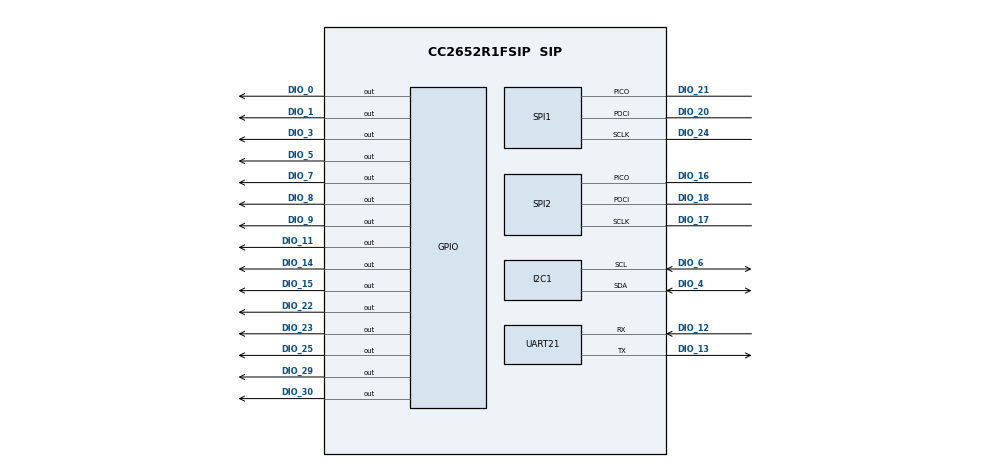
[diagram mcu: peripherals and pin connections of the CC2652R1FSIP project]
/**
 * @cliArgs --device "CC2652R1FSIP" --package "SIP" --part "Default" --rtos "tirtos7" --product "simplelink_cc13xx_cc26xx_sdk@7.41.00.17"
 * @versions {"tool":"1.18.1+3343"}
 */

/**
 * Import the modules used in this configuration.
 */
const ble            = scripting.addModule("/ti/ble5stack/ble");
const CCFG           = scripting.addModule("/ti/devices/CCFG");
const rfdesign       = scripting.addModule("/ti/devices/radioconfig/rfdesign");
const ADC            = scripting.addModule("/ti/drivers/ADC", {}, false);
const ADC1           = ADC.addInstance();
const AESCBC         = scripting.addModule("/ti/drivers/AESCBC", {}, false);
const AESCBC1        = AESCBC.addInstance();
const AESCCM         = scripting.addModule("/ti/drivers/AESCCM");
const AESCCM1        = AESCCM.addInstance();
const AESCTRDRBG     = scripting.addModule("/ti/drivers/AESCTRDRBG");
const AESCTRDRBG1    = AESCTRDRBG.addInstance();
const AESECB         = scripting.addModule("/ti/drivers/AESECB");
const AESECB1        = AESECB.addInstance();
const Board          = scripting.addModule("/ti/drivers/Board");
const ECDH           = scripting.addModule("/ti/drivers/ECDH");
const ECDH1          = ECDH.addInstance();
const GPIO           = scripting.addModule("/ti/drivers/GPIO");
const GPIO2          = GPIO.addInstance();
const GPIO3          = GPIO.addInstance();
const GPIO4          = GPIO.addInstance();
const GPIO5          = GPIO.addInstance();
const GPIO6          = GPIO.addInstance();
const GPIO7          = GPIO.addInstance();
const GPIO8          = GPIO.addInstance();
const GPIO9          = GPIO.addInstance();
const GPIO10         = GPIO.addInstance();
const GPIO11         = GPIO.addInstance();
const GPIO12         = GPIO.addInstance();
const GPIO13         = GPIO.addInstance();
const GPIO14         = GPIO.addInstance();
const GPIO15         = GPIO.addInstance();
const GPIO16         = GPIO.addInstance();
const I2C            = scripting.addModule("/ti/drivers/I2C", {}, false);
const I2C1           = I2C.addInstance();
const NVS            = scripting.addModule("/ti/drivers/NVS");
const NVS1           = NVS.addInstance();
const NVS2           = NVS.addInstance();
const Power          = scripting.addModule("/ti/drivers/Power");
const RF             = scripting.addModule("/ti/drivers/RF");
const SPI            = scripting.addModule("/ti/drivers/SPI", {}, false);
const SPI1           = SPI.addInstance();
const SPI2           = SPI.addInstance();
const TRNG           = scripting.addModule("/ti/drivers/TRNG");
const TRNG1          = TRNG.addInstance();
const TRNG2          = TRNG.addInstance();
const Timer          = scripting.addModule("/ti/drivers/Timer", {}, false);
const Timer1         = Timer.addInstance();
const UART2          = scripting.addModule("/ti/drivers/UART2", {}, false);
const UART21         = UART2.addInstance();
const Watchdog       = scripting.addModule("/ti/drivers/Watchdog", {}, false);
const Watchdog1      = Watchdog.addInstance();
const GPTimerCC26XX  = scripting.addModule("/ti/drivers/timer/GPTimerCC26XX", {}, false);
const GPTimerCC26XX2 = GPTimerCC26XX.addInstance();
const Settings       = scripting.addModule("/ti/posix/tirtos/Settings");
const BIOS           = scripting.addModule("/ti/sysbios/BIOS");
const GateMutexPri   = scripting.addModule("/ti/sysbios/gates/GateMutexPri");
const HeapCallback   = scripting.addModule("/ti/sysbios/heaps/HeapCallback");
const Event          = scripting.addModule("/ti/sysbios/knl/Event");
const Idle           = scripting.addModule("/ti/sysbios/knl/Idle", {}, false);
const Idle2          = Idle.addInstance();
const Mailbox        = scripting.addModule("/ti/sysbios/knl/Mailbox");
const Task           = scripting.addModule("/ti/sysbios/knl/Task");
const Error          = scripting.addModule("/ti/sysbios/runtime/Error");
const Startup        = scripting.addModule("/ti/sysbios/runtime/Startup");
const SysCallback    = scripting.addModule("/ti/sysbios/runtime/SysCallback");
const Timestamp      = scripting.addModule("/ti/sysbios/runtime/Timestamp");

/**
 * Write custom configuration values to the imported modules.
 */
ble.lockProject                                       = true;
ble.addressMode                                       = "ADDRMODE_PUBLIC";
ble.tbmActiveItemsOnly                                = false;
ble.numOfAdvSets                                      = 1;
ble.deviceName                                        = "RFstar_76DA";
ble.extAdv                                            = false;
ble.maxConnNum                                        = 2;
ble.maxPDUSize                                        = 251;
ble.allowDebugKeys                                    = false;
ble.bondMITMProtection                                = false;
ble.bonding                                           = false;
ble.radioConfig.codeExportConfig.$name                = "ti_devices_radioconfig_code_export_param0";
ble.connUpdateParamsPeripheral.$name                  = "ti_ble5stack_general_ble_conn_update_params0";
ble.connUpdateParamsPeripheral.reqMinConnInt          = 20;
ble.connUpdateParamsPeripheral.reqMaxConnInt          = 50;
ble.connUpdateParamsPeripheral.reqConnTo              = 3000;
ble.advSet1.$name                                     = "ti_ble5stack_broadcaster_advertisement_set0";
ble.advSet1.advParam1.$name                           = "ti_ble5stack_broadcaster_advertisement_params0";
ble.advSet1.advParam1.primIntMax                      = 300;
ble.advSet1.advData1.$name                            = "ti_ble5stack_broadcaster_advertisement_data0";
ble.advSet1.advData1.advertisingFlags                 = ["GAP_ADTYPE_FLAGS_BREDR_NOT_SUPPORTED","GAP_ADTYPE_FLAGS_GENERAL"];
ble.advSet1.advData1.shortenedLocalName               = "SP";
ble.advSet1.advData1.numOfUUIDs16More                 = 1;
ble.advSet1.advData1.companyIdentifier                = 0xAA55;
ble.advSet1.advData1.GAP_ADTYPE_MANUFACTURER_SPECIFIC = true;
ble.advSet1.advData1.GAP_ADTYPE_FLAGS                 = true;
ble.advSet1.advData1.UUID016More                      = 0xFFF0;
ble.advSet1.advData1.GAP_ADTYPE_128BIT_MORE           = true;
ble.advSet1.advData1.numOfUUIDs128More                = 1;
ble.advSet1.advData1.UUID0128More                     = system.utils.bigInt("9ECADC240EE5A9E093F3A3B50100406E",16);
ble.advSet1.advData1.additionalData                   = "0x0000000000";
ble.advSet1.scanRes1.$name                            = "ti_ble5stack_broadcaster_advertisement_data1";
ble.advSet1.scanRes1.GAP_ADTYPE_LOCAL_NAME_COMPLETE   = true;
ble.advSet1.scanRes1.maxConnInterval                  = 130;
ble.advSet1.scanRes1.numOfUUIDs16Complete             = 2;
ble.advSet1.scanRes1.UUID116Complete                  = 0x22;
ble.advSet1.scanRes1.GAP_ADTYPE_16BIT_COMPLETE        = true;
scripting.suppress("The example app code handles 2 advertisement sets\\. Please make sure to update the example app code according to the configured number of sets\\.", ble, "numOfAdvSets");

CCFG.enableBootloader         = true;
CCFG.enableBootloaderBackdoor = true;
CCFG.dioBootloaderBackdoor    = 15;
CCFG.levelBootloaderBackdoor  = "Active low";
CCFG.forceVddr                = true;
CCFG.ccfgTemplate.$name       = "ti_devices_CCFG_CCFGCC26XXTemplate0";

ADC1.$name = "CONFIG_ADC_V_TEMP";

AESCBC1.$name = "CONFIG_AESCBC_0";

AESCCM1.$name = "CONFIG_AESCCM0";

AESCTRDRBG1.$name = "CONFIG_AESCTRDRBG_0";

AESECB1.$name = "CONFIG_AESECB0";

ECDH1.$name = "CONFIG_ECDH0";

GPIO2.initialOutputState = "High";
GPIO2.$name              = "CONFIG_GPIO_SPI_IRQ";
GPIO2.interruptTrigger   = "Rising Edge";
GPIO2.pull               = "Pull Up";
GPIO2.gpioPin.$assign    = "DIO_22";

GPIO3.$name              = "CONFIG_GPIO_STIM_CS";
GPIO3.mode               = "Output";
GPIO3.initialOutputState = "High";
GPIO3.gpioPin.$assign    = "DIO_23";

GPIO4.mode            = "Output";
GPIO4.$name           = "CONFIG_GPIO_POWER_3V3_EN";
GPIO4.gpioPin.$assign = "DIO_9";

GPIO5.mode            = "Output";
GPIO5.$name           = "CONFIG_GPIO_RGB_G";
GPIO5.gpioPin.$assign = "DIO_14";

GPIO6.mode            = "Output";
GPIO6.$name           = "CONFIG_GPIO_RGB_O";
GPIO6.gpioPin.$assign = "DIO_15";

GPIO7.mode               = "Output";
GPIO7.outputType         = "Open Drain";
GPIO7.initialOutputState = "High";
GPIO7.pull               = "Pull Up";
GPIO7.$name              = "CONFIG_GPIO_RGB_B";
GPIO7.gpioPin.$assign    = "DIO_11";

GPIO8.$name           = "CONFIG_GPIO_C_STAT";
GPIO8.gpioPin.$assign = "DIO_7";

GPIO9.$name           = "CONFIG_GPIO_KEY_MF_EN";
GPIO9.gpioPin.$assign = "DIO_0";

GPIO10.$name           = "CONFIG_GPIO_KEY_UP";
GPIO10.gpioPin.$assign = "DIO_3";

GPIO11.$name           = "CONFIG_GPIO_KEY_DOWN";
GPIO11.pull            = "Pull Up";
GPIO11.gpioPin.$assign = "DIO_8";

GPIO12.$name           = "CONFIG_GPIO_RTC_INT_CONST";
GPIO12.gpioPin.$assign = "DIO_29";

GPIO13.$name              = "CONFIG_GPIO_EN_5V";
GPIO13.mode               = "Output";
GPIO13.outputStrength     = "High";
GPIO13.initialOutputState = "High";
GPIO13.gpioPin.$assign    = "DIO_25";

GPIO14.$name           = "CONFIG_GPIO_CH_SENSE";
GPIO14.pull            = "Pull Down";
GPIO14.gpioPin.$assign = "DIO_1";

GPIO15.$name           = "CONFIG_GPIO_ALRT";
GPIO15.gpioPin.$assign = "DIO_5";

GPIO16.$name           = "CONFIG_GPIO_KEY_LOCK";
GPIO16.gpioPin.$assign = "DIO_30";

I2C1.$name               = "CONFIG_I2C_RTC";
I2C1.i2c.sdaPin.$assign  = "DIO_4";
I2C1.i2c.sclPin.$assign  = "DIO_6";
I2C1.sclPinInstance.mode = "Output";

NVS1.$name                    = "CONFIG_NVSINTERNAL";
NVS1.internalFlash.$name      = "ti_drivers_nvs_NVSCC26XX0";
NVS1.internalFlash.regionBase = 0x48000;
NVS1.internalFlash.regionSize = 0x4000;

NVS2.nvsType                       = "External";
NVS2.$name                         = "CONFIG_NVSEXTERNAL";
NVS2.externalFlash.$name           = "ti_drivers_nvs_NVSSPI25X0";
NVS2.externalFlash.regionSize      = 0x400000;
NVS2.externalFlash.statusPollDelay = 10;

SPI1.$name                    = "CONFIG_SPI_STIM";
SPI1.spi.$assign              = "SSI1";
SPI1.spi.sclkPin.$assign      = "DIO_24";
SPI1.spi.pociPin.$assign      = "DIO_20";
SPI1.spi.picoPin.$assign      = "DIO_21";
SPI1.spi.dmaRxChannel.$assign = "DMA_CH16";
SPI1.pociPinInstance.pull     = "Pull Up";

TRNG1.$name = "CONFIG_TRNG_0";

TRNG2.$name = "CONFIG_TRNG_1";

Timer1.$name                       = "CONFIG_TIMER_PWM";
Timer1.timerInstance.$name         = "CONFIG_GPTIMER_PWM";
Timer1.timerInstance.timer.$assign = "GPTM1";

UART21.$name                    = "CONFIG_UART2_0_SHELL_LOG";
UART21.txRingBufferSize         = 128;
UART21.rxInterruptFifoThreshold = "7/8";
UART21.rxRingBufferSize         = 1204;
UART21.uart.$assign             = "UART0";
UART21.uart.txPin.$assign       = "DIO_13";
UART21.uart.rxPin.$assign       = "DIO_12";

Watchdog1.$name = "CONFIG_WATCHDOG_0";

const NVSSPI25XDevice                        = scripting.addModule("/ti/drivers/nvs/NVSSPI25XDevice", {}, false);
const NVSSPI25XDevice1                       = NVSSPI25XDevice.addInstance({}, false);
NVSSPI25XDevice1.$name                       = "CONFIG_NVS_SPI_1";
NVS2.externalFlash.spiFlashDevice            = NVSSPI25XDevice1;
NVSSPI25XDevice1.chipSelect.$assign          = "DIO_19";
NVSSPI25XDevice1.chipSelectPinInstance.$name = "CONFIG_GPIO_FLASH_CS";

SPI2.$name                         = "CONFIG_SPI_FLASH";
NVSSPI25XDevice1.sharedSpiInstance = SPI2;
SPI2.spi.$assign                   = "SSI0";
SPI2.spi.sclkPin.$assign           = "DIO_17";
SPI2.spi.pociPin.$assign           = "DIO_18";
SPI2.spi.picoPin.$assign           = "DIO_16";
SPI2.sclkPinInstance.outputSlew    = true;

GPTimerCC26XX2.$name             = "CONFIG_GPTIMER_CAPTURE";
GPTimerCC26XX2.interruptPriority = "6";
GPTimerCC26XX2.timer.$assign     = "GPTM2";

BIOS.assertsEnabled = false;
BIOS.rtsGateType    = "BIOS_GateMutexPri";
BIOS.heapSize       = 0x00000000;
BIOS.heapType       = "HeapCallback";

HeapCallback.initFxn           = "osalHeapInitFxn";
HeapCallback.allocInstFxn      = "osalHeapAllocFxn";
HeapCallback.freeInstFxn       = "osalHeapFreeFxn";
HeapCallback.getStatsInstFxn   = "osalHeapGetStatsFxn";
HeapCallback.isBlockingInstFxn = "osalHeapIsBlockingFxn";

const Clock       = scripting.addModule("/ti/sysbios/knl/Clock", {}, false);
Clock.tickPeriod  = 10;
Clock.swiPriority = 5;

const Timer_1       = scripting.addModule("/ti/sysbios/family/arm/cc26xx/Timer", {}, false);
Timer_1.rtc.$assign = "RTC0";

Idle2.$name   = "powerIdle";
Idle2.idleFxn = "Power_idleFunc";

const Semaphore            = scripting.addModule("/ti/sysbios/knl/Semaphore", {}, false);
Semaphore.supportsPriority = false;

const Swi         = scripting.addModule("/ti/sysbios/knl/Swi", {}, false);
Swi.numPriorities = 6;

Task.numPriorities = 6;

Error.policy       = "Error_SPIN";
Error.printDetails = false;

const System           = scripting.addModule("/ti/sysbios/runtime/System", {}, false);
System.abortFxn        = "System_abortSpin";
System.exitFxn         = "System_exitSpin";
System.extendedFormats = "%f";
System.supportModule   = "SysCallback";

/**
 * Pinmux solution for unlocked pins/peripherals. This ensures that minor changes to the automatic solver in a future
 * version of the tool will not impact the pinmux you originally saw.  These lines can be completely deleted in order to
 * re-solve from scratch.
 */
ADC1.adc.$suggestSolution              = "ADC0";
ADC1.adc.adcPin.$suggestSolution       = "DIO_26";
I2C1.i2c.$suggestSolution              = "I2C0";
SPI1.spi.dmaTxChannel.$suggestSolution = "DMA_CH17";
Watchdog1.watchdog.$suggestSolution    = "WDT0";
SPI2.spi.dmaRxChannel.$suggestSolution = "DMA_CH3";
SPI2.spi.dmaTxChannel.$suggestSolution = "DMA_CH4";
